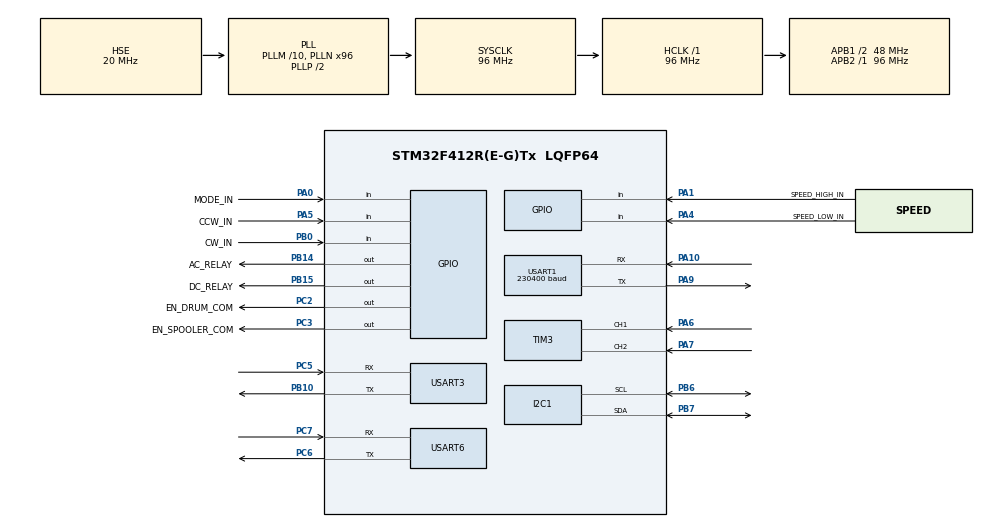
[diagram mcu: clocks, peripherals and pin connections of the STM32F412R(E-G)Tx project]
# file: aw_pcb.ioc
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Dma.Request0=USART1_RX
Dma.Request1=USART1_TX
Dma.USART1_RX.0.Direction=DMA_PERIPH_TO_MEMORY
Dma.USART1_RX.0.FIFOMode=DMA_FIFOMODE_DISABLE
Dma.USART1_RX.0.Instance=DMA2_Stream2
Dma.USART1_RX.0.MemDataAlignment=DMA_MDATAALIGN_BYTE
Dma.USART1_RX.0.MemInc=DMA_MINC_ENABLE
Dma.USART1_RX.0.Mode=DMA_NORMAL
Dma.USART1_RX.0.PeriphDataAlignment=DMA_PDATAALIGN_BYTE
Dma.USART1_RX.0.PeriphInc=DMA_PINC_DISABLE
Dma.USART1_RX.0.Priority=DMA_PRIORITY_HIGH
Dma.USART1_TX.1.Direction=DMA_MEMORY_TO_PERIPH
Dma.USART1_TX.1.FIFOMode=DMA_FIFOMODE_DISABLE
Dma.USART1_TX.1.Instance=DMA2_Stream7
Dma.USART1_TX.1.MemDataAlignment=DMA_MDATAALIGN_BYTE
Dma.USART1_TX.1.MemInc=DMA_MINC_ENABLE
Dma.USART1_TX.1.Mode=DMA_NORMAL
Dma.USART1_TX.1.PeriphDataAlignment=DMA_PDATAALIGN_BYTE
Dma.USART1_TX.1.PeriphInc=DMA_PINC_DISABLE
Dma.USART1_TX.1.Priority=DMA_PRIORITY_HIGH
I2C1.I2C_Mode=I2C_Fast
Mcu.Family=STM32F4
Mcu.Name=STM32F412R(E-G)Tx
Mcu.Package=LQFP64
NVIC.DMA2_Stream2_IRQn=true\:1\:0\:true\:false\:true\:false\:true\:true
NVIC.DMA2_Stream7_IRQn=true\:1\:0\:true\:false\:true\:false\:true\:true
NVIC.PriorityGroup=NVIC_PRIORITYGROUP_4
NVIC.TIM6_IRQn=true\:2\:0\:true\:false\:true\:true\:true\:true
NVIC.USART1_IRQn=true\:1\:0\:true\:false\:true\:true\:true\:true
PA0.GPIO_Label=MODE_IN
PA0.GPIO_PuPd=GPIO_PULLUP
PA0.Signal=GPIO_Input
PA1.GPIO_Label=SPEED_HIGH_IN
PA1.GPIO_PuPd=GPIO_PULLUP
PA1.Signal=GPIO_Input
PA10.Mode=Asynchronous
PA10.Signal=USART1_RX
PA13.Mode=JTAG_4_pins
PA13.Signal=SYS_JTMS-SWDIO
PA14.Mode=JTAG_4_pins
PA14.Signal=SYS_JTCK-SWCLK
PA15.Mode=JTAG_4_pins
PA15.Signal=SYS_JTDI
PA4.GPIO_Label=SPEED_LOW_IN
PA4.GPIO_PuPd=GPIO_PULLUP
PA4.Signal=GPIO_Input
PA5.GPIO_Label=CCW_IN
PA5.GPIO_PuPd=GPIO_PULLUP
PA5.Signal=GPIO_Input
PA6.Signal=S_TIM3_CH1
PA7.Signal=S_TIM3_CH2
PA9.Mode=Asynchronous
PA9.Signal=USART1_TX
PB0.GPIO_Label=CW_IN
PB0.GPIO_PuPd=GPIO_PULLUP
PB0.Signal=GPIO_Input
PB10.Mode=Asynchronous
PB10.Signal=USART3_TX
PB14.GPIO_Label=AC_RELAY
PB14.Signal=GPIO_Output
PB15.GPIO_Label=DC_RELAY
PB15.Signal=GPIO_Output
PB3.Mode=JTAG_4_pins
PB3.Signal=SYS_JTDO-SWO
PB6.GPIO_Mode=GPIO_MODE_AF_OD
PB6.GPIO_Pu=GPIO_NOPULL
PB6.GPIO_Speed=GPIO_SPEED_FREQ_VERY_HIGH
PB6.Mode=I2C
PB6.Signal=I2C1_SCL
PB7.GPIO_Mode=GPIO_MODE_AF_OD
PB7.GPIO_Pu=GPIO_NOPULL
PB7.GPIO_Speed=GPIO_SPEED_FREQ_VERY_HIGH
PB7.Mode=I2C
PB7.Signal=I2C1_SDA
PC2.GPIO_Label=EN_DRUM_COM
PC2.Signal=GPIO_Output
PC3.GPIO_Label=EN_SPOOLER_COM
PC3.Signal=GPIO_Output
PC5.Mode=Asynchronous
PC5.Signal=USART3_RX
PC6.Mode=Asynchronous
PC6.Signal=USART6_TX
PC7.Mode=Asynchronous
PC7.Signal=USART6_RX
PH0\ -\ OSC_IN.Mode=HSE-External-Oscillator
PH0\ -\ OSC_IN.Signal=RCC_OSC_IN
PH1\ -\ OSC_OUT.Mode=HSE-External-Oscillator
PH1\ -\ OSC_OUT.Signal=RCC_OSC_OUT
ProjectManager.HeapSize=0x200
ProjectManager.StackSize=0x400
ProjectManager.TargetToolchain=STM32CubeIDE
RCC.AHBFreq_Value=96000000
RCC.APB1CLKDivider=RCC_HCLK_DIV2
RCC.APB1Freq_Value=48000000
RCC.APB1TimFreq_Value=96000000
RCC.APB2Freq_Value=96000000
RCC.APB2TimFreq_Value=96000000
RCC.CortexFreq_Value=96000000
RCC.HCLKFreq_Value=96000000
RCC.HSE_VALUE=20000000
RCC.PLLM=10
RCC.PLLN=96
RCC.PLLQ=7
RCC.PLLSourceVirtual=RCC_PLLSOURCE_HSE
RCC.SYSCLKFreq_VALUE=96000000
RCC.SYSCLKSource=RCC_SYSCLKSOURCE_PLLCLK
RCC.USBFreq_Value=27428571.42857143
RCC.VCOOutputFreq_Value=192000000
SH.S_TIM3_CH1.0=TIM3_CH1,Encoder_Interface
SH.S_TIM3_CH2.0=TIM3_CH2,Encoder_Interface
TIM3.EncoderMode=TIM_ENCODERMODE_TI12
TIM3.IC1Filter=5
TIM3.IC2Filter=5
TIM6.Period=100-1
TIM6.Prescaler=9600
USART1.BaudRate=230400
USART1.VirtualMode=VM_ASYNC
USART3.VirtualMode=VM_ASYNC
USART6.VirtualMode=VM_ASYNC
VP_TIM6_VS_ClockSourceINT.Mode=Enable_Timer
board=custom

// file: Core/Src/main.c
/* USER CODE BEGIN Header */
/**
  ******************************************************************************
  * @file           : main.c
  * @brief          : Main program body
  ******************************************************************************
  * @attention
  *
  * Copyright (c) 2025 STMicroelectronics.
  * All rights reserved.
  *
  * This software is licensed under terms that can be found in the LICENSE file
  * in the root directory of this software component.
  * If no LICENSE file comes with this software, it is provided AS-IS.
  *
  ******************************************************************************
  */
/* USER CODE END Header */
#include "main.h"

I2C_HandleTypeDef hi2c1;

TIM_HandleTypeDef htim3;
TIM_HandleTypeDef htim6;

UART_HandleTypeDef huart1;
UART_HandleTypeDef huart3;
UART_HandleTypeDef huart6;
DMA_HandleTypeDef hdma_usart1_rx;
DMA_HandleTypeDef hdma_usart1_tx;

void SystemClock_Config(void);
static void MX_GPIO_Init(void);
static void MX_DMA_Init(void);
static void MX_I2C1_Init(void);
static void MX_TIM3_Init(void);
static void MX_USART3_UART_Init(void);
static void MX_USART6_UART_Init(void);
static void MX_USART1_UART_Init(void);
static void MX_TIM6_Init(void);

/* USER CODE BEGIN 0 */
#include "src/automated_winch/automated_winch_inc.h"
#include "src/automated_winch/automated_winch_inc.c"
/* USER CODE END 0 */

int main(void)
{

  /* MCU Configuration--------------------------------------------------------*/

  /* Reset of all peripherals, Initializes the Flash interface and the Systick. */
  HAL_Init();

  /* Configure the system clock */
  SystemClock_Config();

  /* Initialize all configured peripherals */
  MX_GPIO_Init();
  MX_DMA_Init();
  MX_I2C1_Init();
  MX_TIM3_Init();
  MX_USART3_UART_Init();
  MX_USART6_UART_Init();
  MX_USART1_UART_Init();
  MX_TIM6_Init();
  /* USER CODE BEGIN 2 */

    aw_init();

    while(1)
    {
        aw_frame();
    }

  /* USER CODE END 2 */

  /* Infinite loop */
    while (1)
    {

    }
}

void SystemClock_Config(void)
{
  RCC_OscInitTypeDef RCC_OscInitStruct = {0};
  RCC_ClkInitTypeDef RCC_ClkInitStruct = {0};

  /** Configure the main internal regulator output voltage
  */
  __HAL_RCC_PWR_CLK_ENABLE();
  __HAL_PWR_VOLTAGESCALING_CONFIG(PWR_REGULATOR_VOLTAGE_SCALE1);

  /** Initializes the RCC Oscillators according to the specified parameters
  * in the RCC_OscInitTypeDef structure.
  */
  RCC_OscInitStruct.OscillatorType = RCC_OSCILLATORTYPE_HSE;
  RCC_OscInitStruct.HSEState = RCC_HSE_ON;
  RCC_OscInitStruct.PLL.PLLState = RCC_PLL_ON;
  RCC_OscInitStruct.PLL.PLLSource = RCC_PLLSOURCE_HSE;
  RCC_OscInitStruct.PLL.PLLM = 10;
  RCC_OscInitStruct.PLL.PLLN = 96;
  RCC_OscInitStruct.PLL.PLLP = RCC_PLLP_DIV2;
  RCC_OscInitStruct.PLL.PLLQ = 7;
  RCC_OscInitStruct.PLL.PLLR = 2;
  if (HAL_RCC_OscConfig(&RCC_OscInitStruct) != HAL_OK)
  {
    Error_Handler();
  }

  /** Initializes the CPU, AHB and APB buses clocks
  */
  RCC_ClkInitStruct.ClockType = RCC_CLOCKTYPE_HCLK|RCC_CLOCKTYPE_SYSCLK
                              |RCC_CLOCKTYPE_PCLK1|RCC_CLOCKTYPE_PCLK2;
  RCC_ClkInitStruct.SYSCLKSource = RCC_SYSCLKSOURCE_PLLCLK;
  RCC_ClkInitStruct.AHBCLKDivider = RCC_SYSCLK_DIV1;
  RCC_ClkInitStruct.APB1CLKDivider = RCC_HCLK_DIV2;
  RCC_ClkInitStruct.APB2CLKDivider = RCC_HCLK_DIV1;

  if (HAL_RCC_ClockConfig(&RCC_ClkInitStruct, FLASH_LATENCY_3) != HAL_OK)
  {
    Error_Handler();
  }
}

static void MX_I2C1_Init(void)
{

  hi2c1.Instance = I2C1;
  hi2c1.Init.ClockSpeed = 400000;
  hi2c1.Init.DutyCycle = I2C_DUTYCYCLE_2;
  hi2c1.Init.OwnAddress1 = 0;
  hi2c1.Init.AddressingMode = I2C_ADDRESSINGMODE_7BIT;
  hi2c1.Init.DualAddressMode = I2C_DUALADDRESS_DISABLE;
  hi2c1.Init.OwnAddress2 = 0;
  hi2c1.Init.GeneralCallMode = I2C_GENERALCALL_DISABLE;
  hi2c1.Init.NoStretchMode = I2C_NOSTRETCH_DISABLE;
  if (HAL_I2C_Init(&hi2c1) != HAL_OK)
  {
    Error_Handler();
  }

}

static void MX_TIM3_Init(void)
{

  TIM_Encoder_InitTypeDef sConfig = {0};
  TIM_MasterConfigTypeDef sMasterConfig = {0};

  htim3.Instance = TIM3;
  htim3.Init.Prescaler = 0;
  htim3.Init.CounterMode = TIM_COUNTERMODE_UP;
  htim3.Init.Period = 65535;
  htim3.Init.ClockDivision = TIM_CLOCKDIVISION_DIV1;
  htim3.Init.AutoReloadPreload = TIM_AUTORELOAD_PRELOAD_DISABLE;
  sConfig.EncoderMode = TIM_ENCODERMODE_TI12;
  sConfig.IC1Polarity = TIM_ICPOLARITY_RISING;
  sConfig.IC1Selection = TIM_ICSELECTION_DIRECTTI;
  sConfig.IC1Prescaler = TIM_ICPSC_DIV1;
  sConfig.IC1Filter = 5;
  sConfig.IC2Polarity = TIM_ICPOLARITY_RISING;
  sConfig.IC2Selection = TIM_ICSELECTION_DIRECTTI;
  sConfig.IC2Prescaler = TIM_ICPSC_DIV1;
  sConfig.IC2Filter = 5;
  if (HAL_TIM_Encoder_Init(&htim3, &sConfig) != HAL_OK)
  {
    Error_Handler();
  }
  sMasterConfig.MasterOutputTrigger = TIM_TRGO_RESET;
  sMasterConfig.MasterSlaveMode = TIM_MASTERSLAVEMODE_DISABLE;
  if (HAL_TIMEx_MasterConfigSynchronization(&htim3, &sMasterConfig) != HAL_OK)
  {
    Error_Handler();
  }

}

static void MX_TIM6_Init(void)
{

  TIM_MasterConfigTypeDef sMasterConfig = {0};

  htim6.Instance = TIM6;
  htim6.Init.Prescaler = 9600;
  htim6.Init.CounterMode = TIM_COUNTERMODE_UP;
  htim6.Init.Period = 100-1;
  htim6.Init.AutoReloadPreload = TIM_AUTORELOAD_PRELOAD_DISABLE;
  if (HAL_TIM_Base_Init(&htim6) != HAL_OK)
  {
    Error_Handler();
  }
  sMasterConfig.MasterOutputTrigger = TIM_TRGO_RESET;
  sMasterConfig.MasterSlaveMode = TIM_MASTERSLAVEMODE_DISABLE;
  if (HAL_TIMEx_MasterConfigSynchronization(&htim6, &sMasterConfig) != HAL_OK)
  {
    Error_Handler();
  }

}

static void MX_USART1_UART_Init(void)
{

  huart1.Instance = USART1;
  huart1.Init.BaudRate = 230400;
  huart1.Init.WordLength = UART_WORDLENGTH_8B;
  huart1.Init.StopBits = UART_STOPBITS_1;
  huart1.Init.Parity = UART_PARITY_NONE;
  huart1.Init.Mode = UART_MODE_TX_RX;
  huart1.Init.HwFlowCtl = UART_HWCONTROL_NONE;
  huart1.Init.OverSampling = UART_OVERSAMPLING_16;
  if (HAL_UART_Init(&huart1) != HAL_OK)
  {
    Error_Handler();
  }

}

static void MX_USART3_UART_Init(void)
{

  huart3.Instance = USART3;
  huart3.Init.BaudRate = 115200;
  huart3.Init.WordLength = UART_WORDLENGTH_8B;
  huart3.Init.StopBits = UART_STOPBITS_1;
  huart3.Init.Parity = UART_PARITY_NONE;
  huart3.Init.Mode = UART_MODE_TX_RX;
  huart3.Init.HwFlowCtl = UART_HWCONTROL_NONE;
  huart3.Init.OverSampling = UART_OVERSAMPLING_16;
  if (HAL_UART_Init(&huart3) != HAL_OK)
  {
    Error_Handler();
  }

}

static void MX_USART6_UART_Init(void)
{

  huart6.Instance = USART6;
  huart6.Init.BaudRate = 115200;
  huart6.Init.WordLength = UART_WORDLENGTH_8B;
  huart6.Init.StopBits = UART_STOPBITS_1;
  huart6.Init.Parity = UART_PARITY_NONE;
  huart6.Init.Mode = UART_MODE_TX_RX;
  huart6.Init.HwFlowCtl = UART_HWCONTROL_NONE;
  huart6.Init.OverSampling = UART_OVERSAMPLING_16;
  if (HAL_UART_Init(&huart6) != HAL_OK)
  {
    Error_Handler();
  }

}

static void MX_DMA_Init(void)
{

  /* DMA controller clock enable */
  __HAL_RCC_DMA2_CLK_ENABLE();

  /* DMA interrupt init */
  /* DMA2_Stream2_IRQn interrupt configuration */
  HAL_NVIC_SetPriority(DMA2_Stream2_IRQn, 1, 0);
  HAL_NVIC_EnableIRQ(DMA2_Stream2_IRQn);
  /* DMA2_Stream7_IRQn interrupt configuration */
  HAL_NVIC_SetPriority(DMA2_Stream7_IRQn, 1, 0);
  HAL_NVIC_EnableIRQ(DMA2_Stream7_IRQn);

}

static void MX_GPIO_Init(void)
{
  GPIO_InitTypeDef GPIO_InitStruct = {0};

  /* GPIO Ports Clock Enable */
  __HAL_RCC_GPIOH_CLK_ENABLE();
  __HAL_RCC_GPIOC_CLK_ENABLE();
  __HAL_RCC_GPIOA_CLK_ENABLE();
  __HAL_RCC_GPIOB_CLK_ENABLE();

  /*Configure GPIO pin Output Level */
  HAL_GPIO_WritePin(GPIOC, EN_DRUM_COM_Pin|EN_SPOOLER_COM_Pin, GPIO_PIN_RESET);

  /*Configure GPIO pin Output Level */
  HAL_GPIO_WritePin(GPIOB, AC_RELAY_Pin|DC_RELAY_Pin, GPIO_PIN_RESET);

  /*Configure GPIO pins : EN_DRUM_COM_Pin EN_SPOOLER_COM_Pin */
  GPIO_InitStruct.Pin = EN_DRUM_COM_Pin|EN_SPOOLER_COM_Pin;
  GPIO_InitStruct.Mode = GPIO_MODE_OUTPUT_PP;
  GPIO_InitStruct.Pull = GPIO_NOPULL;
  GPIO_InitStruct.Speed = GPIO_SPEED_FREQ_LOW;
  HAL_GPIO_Init(GPIOC, &GPIO_InitStruct);

  /*Configure GPIO pins : MODE_IN_Pin SPEED_HIGH_IN_Pin SPEED_LOW_IN_Pin CCW_IN_Pin */
  GPIO_InitStruct.Pin = MODE_IN_Pin|SPEED_HIGH_IN_Pin|SPEED_LOW_IN_Pin|CCW_IN_Pin;
  GPIO_InitStruct.Mode = GPIO_MODE_INPUT;
  GPIO_InitStruct.Pull = GPIO_PULLUP;
  HAL_GPIO_Init(GPIOA, &GPIO_InitStruct);

  /*Configure GPIO pin : CW_IN_Pin */
  GPIO_InitStruct.Pin = CW_IN_Pin;
  GPIO_InitStruct.Mode = GPIO_MODE_INPUT;
  GPIO_InitStruct.Pull = GPIO_PULLUP;
  HAL_GPIO_Init(CW_IN_GPIO_Port, &GPIO_InitStruct);

  /*Configure GPIO pins : AC_RELAY_Pin DC_RELAY_Pin */
  GPIO_InitStruct.Pin = AC_RELAY_Pin|DC_RELAY_Pin;
  GPIO_InitStruct.Mode = GPIO_MODE_OUTPUT_PP;
  GPIO_InitStruct.Pull = GPIO_NOPULL;
  GPIO_InitStruct.Speed = GPIO_SPEED_FREQ_LOW;
  HAL_GPIO_Init(GPIOB, &GPIO_InitStruct);

}

void Error_Handler(void)
{
    __disable_irq();
    while (1)
    {
    }
}
